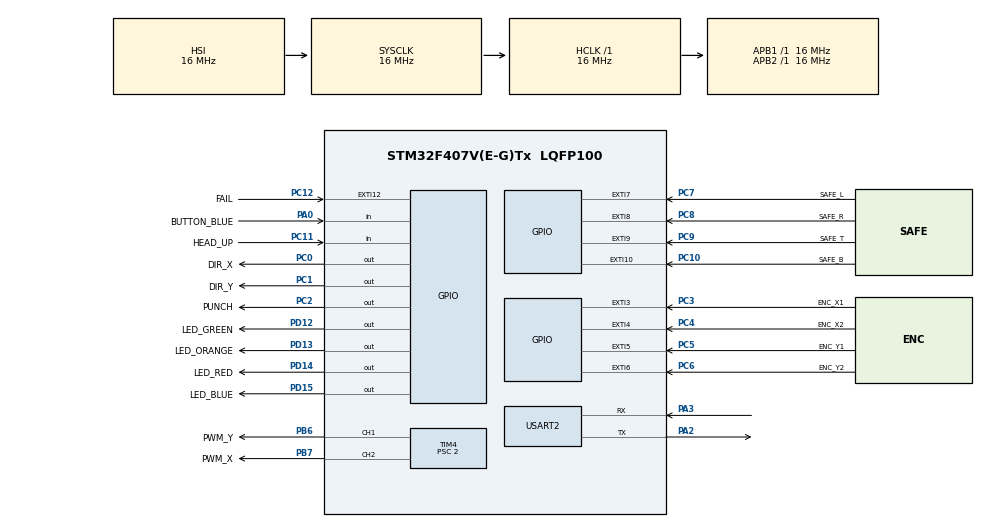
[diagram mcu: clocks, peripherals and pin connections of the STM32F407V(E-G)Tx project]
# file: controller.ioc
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Mcu.Family=STM32F4
Mcu.Name=STM32F407V(E-G)Tx
Mcu.Package=LQFP100
NVIC.EXTI15_10_IRQn=true\:0\:0\:false\:false\:true\:true\:true\:true
NVIC.EXTI3_IRQn=true\:0\:0\:false\:false\:true\:true\:true\:true
NVIC.EXTI4_IRQn=true\:0\:0\:false\:false\:true\:true\:true\:true
NVIC.EXTI9_5_IRQn=true\:0\:0\:false\:false\:true\:true\:true\:true
NVIC.PriorityGroup=NVIC_PRIORITYGROUP_4
PA0-WKUP.GPIO_Label=BUTTON_BLUE
PA0-WKUP.Signal=GPIO_Input
PA2.Mode=Asynchronous
PA2.Signal=USART2_TX
PA3.Mode=Asynchronous
PA3.Signal=USART2_RX
PB6.GPIO_Label=PWM_Y
PB6.GPIO_Speed=GPIO_SPEED_FREQ_LOW
PB6.Signal=S_TIM4_CH1
PB7.GPIO_Label=PWM_X
PB7.GPIO_Speed=GPIO_SPEED_FREQ_LOW
PB7.Signal=S_TIM4_CH2
PC0.GPIO_Label=DIR_X
PC0.PinState=GPIO_PIN_RESET
PC0.Signal=GPIO_Output
PC1.GPIO_Label=DIR_Y
PC1.PinState=GPIO_PIN_RESET
PC1.Signal=GPIO_Output
PC10.GPIO_Label=SAFE_B
PC10.Signal=GPXTI10
PC11.GPIO_Label=HEAD_UP
PC11.Signal=GPIO_Input
PC12.GPIO_Label=FAIL
PC12.GPIO_ModeDefaultEXTI=GPIO_MODE_IT_RISING
PC12.Signal=GPXTI12
PC2.GPIO_Label=PUNCH
PC2.Signal=GPIO_Output
PC3.GPIO_Label=ENC_X1
PC3.GPIO_ModeDefaultEXTI=GPIO_MODE_IT_RISING_FALLING
PC3.Signal=GPXTI3
PC4.GPIO_Label=ENC_X2
PC4.GPIO_ModeDefaultEXTI=GPIO_MODE_IT_RISING_FALLING
PC4.Signal=GPXTI4
PC5.GPIO_Label=ENC_Y1
PC5.GPIO_ModeDefaultEXTI=GPIO_MODE_IT_RISING_FALLING
PC5.Signal=GPXTI5
PC6.GPIO_Label=ENC_Y2
PC6.GPIO_ModeDefaultEXTI=GPIO_MODE_IT_RISING_FALLING
PC6.Signal=GPXTI6
PC7.GPIO_Label=SAFE_L
PC7.Signal=GPXTI7
PC8.GPIO_Label=SAFE_R
PC8.Signal=GPXTI8
PC9.GPIO_Label=SAFE_T
PC9.Signal=GPXTI9
PD12.GPIO_Label=LED_GREEN
PD12.Signal=GPIO_Output
PD13.GPIO_Label=LED_ORANGE
PD13.Signal=GPIO_Output
PD14.GPIO_Label=LED_RED
PD14.Signal=GPIO_Output
PD15.GPIO_Label=LED_BLUE
PD15.Signal=GPIO_Output
ProjectManager.HeapSize=0x200
ProjectManager.StackSize=0x400
ProjectManager.TargetToolchain=STM32CubeIDE
RCC.48MHZClocksFreq_Value=48000000
RCC.AHBFreq_Value=16000000
RCC.APB1Freq_Value=16000000
RCC.APB1TimCLKDivider=1
RCC.APB1TimFreq_Value=16000000
RCC.APB2Freq_Value=16000000
RCC.APB2TimCLKDivider=1
RCC.APB2TimFreq_Value=16000000
RCC.CortexFreq_Value=16000000
RCC.HCLKFreq_Value=16000000
RCC.HSE_VALUE=25000000
RCC.HSI_VALUE=16000000
RCC.LSE_VALUE=32768
RCC.SYSCLKFreq_VALUE=16000000
RCC.VCOOutputFreq_Value=192000000
SH.S_TIM4_CH1.0=TIM4_CH1,PWM Generation1 CH1
SH.S_TIM4_CH2.0=TIM4_CH2,PWM Generation2 CH2
TIM4.AutoReloadPreload=TIM_AUTORELOAD_PRELOAD_DISABLE
TIM4.Channel-PWM\ Generation1\ CH1=TIM_CHANNEL_1
TIM4.Channel-PWM\ Generation2\ CH2=TIM_CHANNEL_2
TIM4.ClockDivision=TIM_CLOCKDIVISION_DIV1
TIM4.OC1Preload_PWM=DISABLE
TIM4.OC2Preload_PWM=DISABLE
TIM4.Period=100
TIM4.Prescaler=2
TIM4.Pulse-PWM\ Generation1\ CH1=50
TIM4.Pulse-PWM\ Generation2\ CH2=50
USART2.VirtualMode=VM_ASYNC
board=custom

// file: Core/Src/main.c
/* USER CODE BEGIN Header */
/**
  ******************************************************************************
  * @file           : main.c
  * @brief          : Main program body
  ******************************************************************************
  * @attention
  *
  * Copyright (c) 2022 STMicroelectronics.
  * All rights reserved.
  *
  * This software is licensed under terms that can be found in the LICENSE file
  * in the root directory of this software component.
  * If no LICENSE file comes with this software, it is provided AS-IS.
  *
  ******************************************************************************
  */
/* USER CODE END Header */
#include "main.h"
#include "tim.h"
#include "usart.h"
#include "gpio.h"

/* USER CODE BEGIN Includes */
#include "controller.h"
#include "log.h"
/* USER CODE END Includes */

void SystemClock_Config(void);

int main(void)
{

  /* MCU Configuration--------------------------------------------------------*/

  /* Reset of all peripherals, Initializes the Flash interface and the Systick. */
  HAL_Init();

  /* Configure the system clock */
  SystemClock_Config();

  /* Initialize all configured peripherals */
  MX_GPIO_Init();
  MX_USART2_UART_Init();
  MX_TIM4_Init();

  /* Infinite loop */
  while (1)
  {

    /* USER CODE BEGIN 3 */
	  handle_main_loop();
  }
  /* USER CODE END 3 */
}

void SystemClock_Config(void)
{
  RCC_OscInitTypeDef RCC_OscInitStruct = {0};
  RCC_ClkInitTypeDef RCC_ClkInitStruct = {0};

  /** Configure the main internal regulator output voltage
  */
  __HAL_RCC_PWR_CLK_ENABLE();
  __HAL_PWR_VOLTAGESCALING_CONFIG(PWR_REGULATOR_VOLTAGE_SCALE1);

  /** Initializes the RCC Oscillators according to the specified parameters
  * in the RCC_OscInitTypeDef structure.
  */
  RCC_OscInitStruct.OscillatorType = RCC_OSCILLATORTYPE_HSI;
  RCC_OscInitStruct.HSIState = RCC_HSI_ON;
  RCC_OscInitStruct.HSICalibrationValue = RCC_HSICALIBRATION_DEFAULT;
  RCC_OscInitStruct.PLL.PLLState = RCC_PLL_NONE;
  if (HAL_RCC_OscConfig(&RCC_OscInitStruct) != HAL_OK)
  {
    Error_Handler();
  }

  /** Initializes the CPU, AHB and APB buses clocks
  */
  RCC_ClkInitStruct.ClockType = RCC_CLOCKTYPE_HCLK|RCC_CLOCKTYPE_SYSCLK
                              |RCC_CLOCKTYPE_PCLK1|RCC_CLOCKTYPE_PCLK2;
  RCC_ClkInitStruct.SYSCLKSource = RCC_SYSCLKSOURCE_HSI;
  RCC_ClkInitStruct.AHBCLKDivider = RCC_SYSCLK_DIV1;
  RCC_ClkInitStruct.APB1CLKDivider = RCC_HCLK_DIV1;
  RCC_ClkInitStruct.APB2CLKDivider = RCC_HCLK_DIV1;

  if (HAL_RCC_ClockConfig(&RCC_ClkInitStruct, FLASH_LATENCY_0) != HAL_OK)
  {
    Error_Handler();
  }
}

void Error_Handler(void)
{
  /* USER CODE BEGIN Error_Handler_Debug */
  /* User can add his own implementation to report the HAL error return state */
  __disable_irq();
  log_error("HAL ERROR HANDLER");
  while (1)
  {
  }
  /* USER CODE END Error_Handler_Debug */
}
